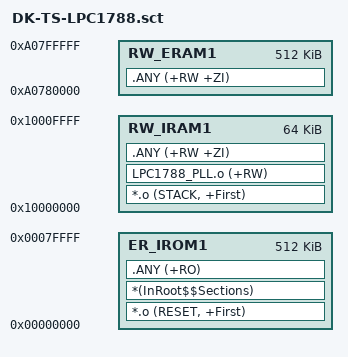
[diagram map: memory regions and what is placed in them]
; *************************************************************
; *** Scatter-Loading Description File generated by uVision ***
; *************************************************************

LR_IROM1 0x00000000 0x00080000  {    ; load region size_region
  ER_IROM1 0x00000000 0x00080000 {  ; load address = execution address
   *.o (RESET, +First)
   *(InRoot$$Sections)
   .ANY (+RO)
  }
  RW_ERAM1 0xA0780000 0x00080000  {  ; RW data, 512K of 8 Megs of SDRAM
   .ANY (+RW +ZI)
   
  }
  RW_IRAM1 0x10000000 0x00010000  {  ; RW data, 64K
   *.o (STACK, +First) ; Put the initial stack in internal memory since SDRAM is not initialized yet
   LPC1788_PLL.o (+RW)
   .ANY (+RW +ZI)
  }
  ; Reserved, directly accessed by USB
  ;AHBSRAM0 0x20000000 0x00004000 {
  ;   .ANY (+RW +ZI)
  ;}
  ; Dedicate this area for the Ethernet device's memory
  ; (and the leftovers can be other memory)

}
